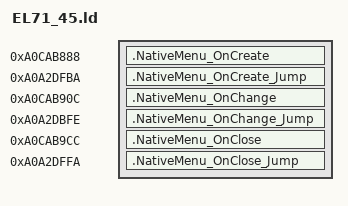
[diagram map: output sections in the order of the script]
SECTIONS {
    .NativeMenu_OnCreate 0xA0CAB888 : {
        KEEP(*(.text.NativeMenu_OnCreate))
    }
    .NativeMenu_OnCreate_Jump 0xA0A2DFBA : {
        KEEP(*(.text.NativeMenu_OnCreate_Jump))
    }

    .NativeMenu_OnChange 0xA0CAB90C : {
        KEEP(*(.text.NativeMenu_OnChange))
        KEEP(*(.rodata*))
    }
    .NativeMenu_OnChange_Jump 0xA0A2DBFE : {
        KEEP(*(.text.NativeMenu_OnChange_Jump))
    }

    .NativeMenu_OnClose 0xA0CAB9CC : {
        KEEP(*(.text.NativeMenu_OnClose))
    }
    .NativeMenu_OnClose_Jump 0xA0A2DFFA : {
        KEEP(*(.text.NativeMenu_OnClose_Jump))
    }
}
